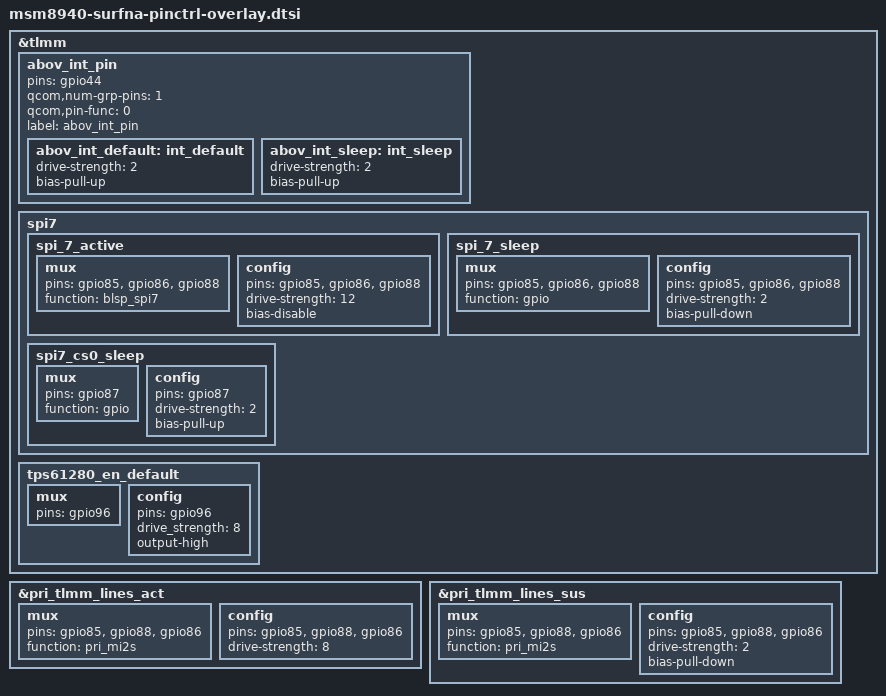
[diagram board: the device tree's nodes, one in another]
/* Copyright (c) 2018, Motorola Mobility Inc. All rights reserved.
 *
 * This program is free software; you can redistribute it and/or modify
 * it under the terms of the GNU General Public License version 2 and
 * only version 2 as published by the Free Software Foundation.
 *
 * This program is distributed in the hope that it will be useful,
 * but WITHOUT ANY WARRANTY; without even the implied warranty of
 * MERCHANTABILITY or FITNESS FOR A PARTICULAR PURPOSE.  See the
 * GNU General Public License for more details.
 */

&tlmm {
	abov_int_pin {
		/* qcom,pins = <&gp 44>;*/
		pins = "gpio44";
		qcom,num-grp-pins = <1>;
		qcom,pin-func = <0>;
		label = "abov_int_pin";
		abov_int_default: int_default {
			drive-strength = <2>;
			bias-pull-up;
		};
		abov_int_sleep: int_sleep {
			drive-strength = <2>;
			bias-pull-up;
		};
	};

	spi7 {
		/* BLSP7 MOSI, MISO, CLK */
		spi_7_active: spi_7_active {
			/* active state */
			mux {
				/* MOSI, MISO, CLK */
				pins = "gpio85", "gpio86", "gpio88";
				function = "blsp_spi7";
			};
			config {
				pins = "gpio85", "gpio86", "gpio88";
				drive-strength = <12>; /* 12 MA */
				bias-disable; /* No PULL */
			};
		};
		spi_7_sleep:spi_7_sleep {
			mux {
				/* MOSI, MISO, CLK */
				pins = "gpio85", "gpio86", "gpio88";
				function = "gpio";
			};
			config {
				pins = "gpio85", "gpio86", "gpio88";
				drive-strength = <2>; /* 2 MA */
				bias-pull-down; /* PULL Down */
			};
		};
		spi7_cs0_sleep: spi7_cs0_sleep {
			/* CS */
			mux {
				pins = "gpio87";
				function = "gpio";
			};
			config {
				pins = "gpio87";
				drive-strength = <2>;
				bias-pull-up;
			};
		};
	};

	tps61280_en_default: tps61280_en_default {
		mux {
			pins = "gpio96";
		};
		config {
			pins = "gpio96";
			drive_strength = <8>;
			output-high;
		};
	};
};

&pri_tlmm_lines_act {
	mux {
		pins = "gpio85", "gpio88", "gpio86";
		function = "pri_mi2s";
	};

	config {
		pins = "gpio85", "gpio88", "gpio86";
		drive-strength = <8>;
	};
};

&pri_tlmm_lines_sus {
	mux {
		pins = "gpio85", "gpio88", "gpio86";
		function = "pri_mi2s";
	};

	config {
		pins = "gpio85", "gpio88", "gpio86";
		drive-strength = <2>;
		bias-pull-down;
	};
};
